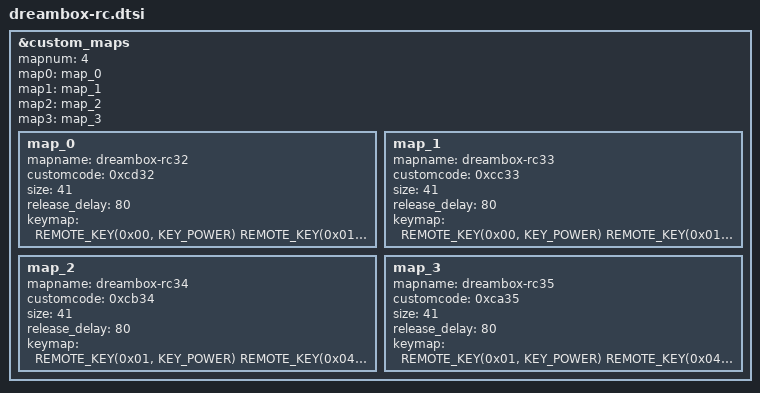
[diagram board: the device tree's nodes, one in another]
/*
 * arch/arm64/boot/dts/amlogic/dreambox-rc.dtsi
 *
 * Copyright (C) 2017 Dream Property GmbH. All rights reserved.
 *
 * This program is free software; you can redistribute it and/or modify
 * it under the terms of the GNU General Public License as published by
 * the Free Software Foundation; either version 2 of the License, or
 * (at your option) any later version.
 *
 * This program is distributed in the hope that it will be useful, but WITHOUT
 * ANY WARRANTY; without even the implied warranty of MERCHANTABILITY or
 * FITNESS FOR A PARTICULAR PURPOSE.  See the GNU General Public License for
 * more details.
 *
 */

&custom_maps {
	mapnum = <4>;
	map0 = <&map_0>;
	map1 = <&map_1>;
	map2 = <&map_2>;
	map3 = <&map_3>;

	map_0: map_0 {
		mapname = "dreambox-rc32";
		customcode = <0xcd32>;
		size = <41>;
		release_delay = <80>;
		keymap = <
			REMOTE_KEY(0x00, KEY_POWER)
			REMOTE_KEY(0x01, KEY_1)
			REMOTE_KEY(0x02, KEY_2)
			REMOTE_KEY(0x03, KEY_3)
			REMOTE_KEY(0x04, KEY_4)
			REMOTE_KEY(0x05, KEY_5)
			REMOTE_KEY(0x06, KEY_6)
			REMOTE_KEY(0x07, KEY_7)
			REMOTE_KEY(0x08, KEY_8)
			REMOTE_KEY(0x09, KEY_9)
			REMOTE_KEY(0x0A, KEY_PREVIOUS)
			REMOTE_KEY(0x0B, KEY_0)
			REMOTE_KEY(0x0C, KEY_NEXT)
			REMOTE_KEY(0x0E, KEY_AUDIO)
			REMOTE_KEY(0x10, KEY_INFO)
			REMOTE_KEY(0x11, KEY_UP)
			REMOTE_KEY(0x12, KEY_MENU)
			REMOTE_KEY(0x13, KEY_LEFT)
			REMOTE_KEY(0x14, KEY_OK)
			REMOTE_KEY(0x15, KEY_RIGHT)
			REMOTE_KEY(0x16, KEY_HELP)
			REMOTE_KEY(0x17, KEY_DOWN)
			REMOTE_KEY(0x18, KEY_VIDEO)
			REMOTE_KEY(0x19, KEY_VOLUMEUP)
			REMOTE_KEY(0x1A, KEY_MUTE)
			REMOTE_KEY(0x1B, KEY_CHANNELUP)
			REMOTE_KEY(0x1C, KEY_VOLUMEDOWN)
			REMOTE_KEY(0x1D, KEY_EXIT)
			REMOTE_KEY(0x1E, KEY_CHANNELDOWN)
			REMOTE_KEY(0x1F, KEY_RED)
			REMOTE_KEY(0x20, KEY_GREEN)
			REMOTE_KEY(0x21, KEY_YELLOW)
			REMOTE_KEY(0x22, KEY_BLUE)
			REMOTE_KEY(0x23, KEY_PREVIOUSSONG)
			REMOTE_KEY(0x24, KEY_PLAY)
			REMOTE_KEY(0x25, KEY_STOP)
			REMOTE_KEY(0x26, KEY_NEXTSONG)
			REMOTE_KEY(0x27, KEY_TV)
			REMOTE_KEY(0x28, KEY_RADIO)
			REMOTE_KEY(0x29, KEY_TEXT)
			REMOTE_KEY(0x2A, KEY_RECORD)
		>;
	};
	map_1: map_1 {
		mapname = "dreambox-rc33";
		customcode = <0xcc33>;
		size = <41>;
		release_delay = <80>;
		keymap = <
			REMOTE_KEY(0x00, KEY_POWER)
			REMOTE_KEY(0x01, KEY_1)
			REMOTE_KEY(0x02, KEY_2)
			REMOTE_KEY(0x03, KEY_3)
			REMOTE_KEY(0x04, KEY_4)
			REMOTE_KEY(0x05, KEY_5)
			REMOTE_KEY(0x06, KEY_6)
			REMOTE_KEY(0x07, KEY_7)
			REMOTE_KEY(0x08, KEY_8)
			REMOTE_KEY(0x09, KEY_9)
			REMOTE_KEY(0x0A, KEY_PREVIOUS)
			REMOTE_KEY(0x0B, KEY_0)
			REMOTE_KEY(0x0C, KEY_NEXT)
			REMOTE_KEY(0x0E, KEY_AUDIO)
			REMOTE_KEY(0x10, KEY_INFO)
			REMOTE_KEY(0x11, KEY_UP)
			REMOTE_KEY(0x12, KEY_MENU)
			REMOTE_KEY(0x13, KEY_LEFT)
			REMOTE_KEY(0x14, KEY_OK)
			REMOTE_KEY(0x15, KEY_RIGHT)
			REMOTE_KEY(0x16, KEY_HELP)
			REMOTE_KEY(0x17, KEY_DOWN)
			REMOTE_KEY(0x18, KEY_VIDEO)
			REMOTE_KEY(0x19, KEY_VOLUMEUP)
			REMOTE_KEY(0x1A, KEY_MUTE)
			REMOTE_KEY(0x1B, KEY_CHANNELUP)
			REMOTE_KEY(0x1C, KEY_VOLUMEDOWN)
			REMOTE_KEY(0x1D, KEY_EXIT)
			REMOTE_KEY(0x1E, KEY_CHANNELDOWN)
			REMOTE_KEY(0x1F, KEY_RED)
			REMOTE_KEY(0x20, KEY_GREEN)
			REMOTE_KEY(0x21, KEY_YELLOW)
			REMOTE_KEY(0x22, KEY_BLUE)
			REMOTE_KEY(0x23, KEY_PREVIOUSSONG)
			REMOTE_KEY(0x24, KEY_PLAY)
			REMOTE_KEY(0x25, KEY_STOP)
			REMOTE_KEY(0x26, KEY_NEXTSONG)
			REMOTE_KEY(0x27, KEY_TV)
			REMOTE_KEY(0x28, KEY_RADIO)
			REMOTE_KEY(0x29, KEY_TEXT)
			REMOTE_KEY(0x2A, KEY_RECORD)
		>;
	};
	map_2: map_2 {
		mapname = "dreambox-rc34";
		customcode = <0xcb34>;
		size = <41>;
		release_delay = <80>;
		keymap = <
			REMOTE_KEY(0x01, KEY_POWER)
			REMOTE_KEY(0x04, KEY_1)
			REMOTE_KEY(0x05, KEY_2)
			REMOTE_KEY(0x06, KEY_3)
			REMOTE_KEY(0x07, KEY_MUTE)
			REMOTE_KEY(0x08, KEY_4)
			REMOTE_KEY(0x09, KEY_5)
			REMOTE_KEY(0x0A, KEY_6)
			REMOTE_KEY(0x0B, KEY_PREVIOUS)
			REMOTE_KEY(0x0C, KEY_7)
			REMOTE_KEY(0x0D, KEY_8)
			REMOTE_KEY(0x0E, KEY_9)
			REMOTE_KEY(0x0F, KEY_NEXT)
			REMOTE_KEY(0x10, KEY_0)
			REMOTE_KEY(0x11, KEY_UP)
			REMOTE_KEY(0x12, KEY_EXIT)
			REMOTE_KEY(0x13, KEY_VOLUMEUP)
			REMOTE_KEY(0x14, KEY_LEFT)
			REMOTE_KEY(0x15, KEY_OK)
			REMOTE_KEY(0x16, KEY_RIGHT)
			REMOTE_KEY(0x17, KEY_CHANNELUP)
			REMOTE_KEY(0x18, KEY_VOLUMEDOWN)
			REMOTE_KEY(0x19, KEY_DOWN)
			REMOTE_KEY(0x1A, KEY_CHANNELDOWN)
			REMOTE_KEY(0x1B, KEY_INFO)
			REMOTE_KEY(0x1C, KEY_MENU)
			REMOTE_KEY(0x1F, KEY_RED)
			REMOTE_KEY(0x20, KEY_GREEN)
			REMOTE_KEY(0x21, KEY_YELLOW)
			REMOTE_KEY(0x22, KEY_BLUE)
			REMOTE_KEY(0x23, KEY_TV)
			REMOTE_KEY(0x24, KEY_RADIO)
			REMOTE_KEY(0x25, KEY_TEXT)
			REMOTE_KEY(0x26, KEY_HELP)
			REMOTE_KEY(0x30, KEY_AUDIO)
			REMOTE_KEY(0x31, KEY_VIDEO)
			REMOTE_KEY(0x32, KEY_PREVIOUSSONG)
			REMOTE_KEY(0x33, KEY_PLAY)
			REMOTE_KEY(0x34, KEY_STOP)
			REMOTE_KEY(0x35, KEY_NEXTSONG)
			REMOTE_KEY(0x36, KEY_RECORD)
		>;
	};
	map_3: map_3 {
		mapname = "dreambox-rc35";
		customcode = <0xca35>;
		size = <41>;
		release_delay = <80>;
		keymap = <
			REMOTE_KEY(0x01, KEY_POWER)
			REMOTE_KEY(0x04, KEY_1)
			REMOTE_KEY(0x05, KEY_2)
			REMOTE_KEY(0x06, KEY_3)
			REMOTE_KEY(0x07, KEY_MUTE)
			REMOTE_KEY(0x08, KEY_4)
			REMOTE_KEY(0x09, KEY_5)
			REMOTE_KEY(0x0A, KEY_6)
			REMOTE_KEY(0x0B, KEY_PREVIOUS)
			REMOTE_KEY(0x0C, KEY_7)
			REMOTE_KEY(0x0D, KEY_8)
			REMOTE_KEY(0x0E, KEY_9)
			REMOTE_KEY(0x0F, KEY_NEXT)
			REMOTE_KEY(0x10, KEY_0)
			REMOTE_KEY(0x11, KEY_UP)
			REMOTE_KEY(0x12, KEY_EXIT)
			REMOTE_KEY(0x13, KEY_VOLUMEUP)
			REMOTE_KEY(0x14, KEY_LEFT)
			REMOTE_KEY(0x15, KEY_OK)
			REMOTE_KEY(0x16, KEY_RIGHT)
			REMOTE_KEY(0x17, KEY_CHANNELUP)
			REMOTE_KEY(0x18, KEY_VOLUMEDOWN)
			REMOTE_KEY(0x19, KEY_DOWN)
			REMOTE_KEY(0x1A, KEY_CHANNELDOWN)
			REMOTE_KEY(0x1B, KEY_INFO)
			REMOTE_KEY(0x1C, KEY_MENU)
			REMOTE_KEY(0x1F, KEY_RED)
			REMOTE_KEY(0x20, KEY_GREEN)
			REMOTE_KEY(0x21, KEY_YELLOW)
			REMOTE_KEY(0x22, KEY_BLUE)
			REMOTE_KEY(0x23, KEY_TV)
			REMOTE_KEY(0x24, KEY_RADIO)
			REMOTE_KEY(0x25, KEY_TEXT)
			REMOTE_KEY(0x26, KEY_HELP)
			REMOTE_KEY(0x30, KEY_AUDIO)
			REMOTE_KEY(0x31, KEY_VIDEO)
			REMOTE_KEY(0x32, KEY_PREVIOUSSONG)
			REMOTE_KEY(0x33, KEY_PLAY)
			REMOTE_KEY(0x34, KEY_STOP)
			REMOTE_KEY(0x35, KEY_NEXTSONG)
			REMOTE_KEY(0x36, KEY_RECORD)
		>;
	};
};
